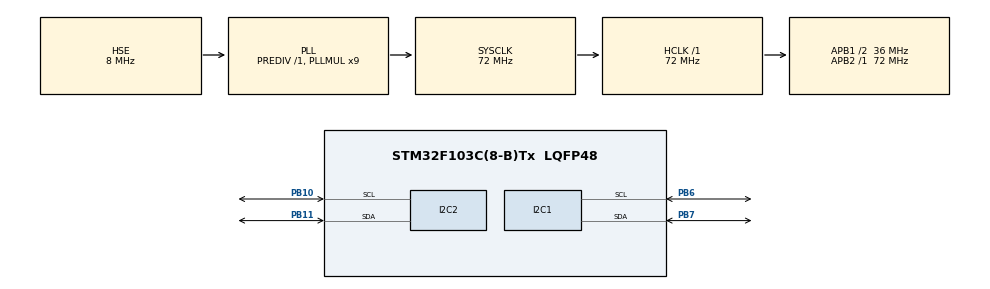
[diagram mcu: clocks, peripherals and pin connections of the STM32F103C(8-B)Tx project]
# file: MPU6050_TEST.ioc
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Mcu.Family=STM32F1
Mcu.Name=STM32F103C(8-B)Tx
Mcu.Package=LQFP48
NVIC.PriorityGroup=NVIC_PRIORITYGROUP_4
PA13.Mode=Serial_Wire
PA13.Signal=SYS_JTMS-SWDIO
PA14.Mode=Serial_Wire
PA14.Signal=SYS_JTCK-SWCLK
PB10.Mode=I2C
PB10.Signal=I2C2_SCL
PB11.Mode=I2C
PB11.Signal=I2C2_SDA
PB6.Mode=I2C
PB6.Signal=I2C1_SCL
PB7.Mode=I2C
PB7.Signal=I2C1_SDA
PC14-OSC32_IN.Mode=LSE-External-Oscillator
PC14-OSC32_IN.Signal=RCC_OSC32_IN
PC15-OSC32_OUT.Mode=LSE-External-Oscillator
PC15-OSC32_OUT.Signal=RCC_OSC32_OUT
PD0-OSC_IN.Mode=HSE-External-Oscillator
PD0-OSC_IN.Signal=RCC_OSC_IN
PD1-OSC_OUT.Mode=HSE-External-Oscillator
PD1-OSC_OUT.Signal=RCC_OSC_OUT
ProjectManager.HeapSize=0x200
ProjectManager.StackSize=0x400
ProjectManager.TargetToolchain=MDK-ARM V5.32
RCC.AHBFreq_Value=72000000
RCC.APB1CLKDivider=RCC_HCLK_DIV2
RCC.APB1Freq_Value=36000000
RCC.APB1TimFreq_Value=72000000
RCC.APB2Freq_Value=72000000
RCC.APB2TimFreq_Value=72000000
RCC.HCLKFreq_Value=72000000
RCC.PLLMUL=RCC_PLL_MUL9
RCC.PLLSourceVirtual=RCC_PLLSOURCE_HSE
RCC.SYSCLKFreq_VALUE=72000000
RCC.SYSCLKSource=RCC_SYSCLKSOURCE_PLLCLK
RCC.USBFreq_Value=72000000
board=custom

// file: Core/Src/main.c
/* USER CODE BEGIN Header */
/**
  ******************************************************************************
  * @file           : main.c
  * @brief          : Main program body
  ******************************************************************************
  * @attention
  *
  * Copyright (c) 2024 STMicroelectronics.
  * All rights reserved.
  *
  * This software is licensed under terms that can be found in the LICENSE file
  * in the root directory of this software component.
  * If no LICENSE file comes with this software, it is provided AS-IS.
  *
  ******************************************************************************
  */
/* USER CODE END Header */
#include "main.h"
#include "i2c.h"
#include "gpio.h"
#include "oled.h"
#include "mpu6050.h"
#include "stdio.h"

uint8_t ID;
uint8_t AX,AY,AZ,GX,GY,GZ,YM;

void SystemClock_Config(void);

int main(void)
{

  /* MCU Configuration--------------------------------------------------------*/

  /* Reset of all peripherals, Initializes the Flash interface and the Systick. */
  HAL_Init();

  /* Configure the system clock */
  SystemClock_Config();

  /* Initialize all configured peripherals */
  MX_GPIO_Init();
  MX_I2C1_Init();
  MX_I2C2_Init();
  /* USER CODE BEGIN 2 */
  HAL_Delay(20);
  OLED_Init();
  MPU6050_Init();

  char message_gx[10];
	char message_gy[10];
	char message_gz[10];
	char message_Ax[10];
	char message_Ay[10];
	char message_Az[10];
  /* USER CODE END 2 */

  /* Infinite loop */
  while (1)
  {
    MPU6050_Read_Accel();
	  MPU6050_Read_Gyro ();
	  sprintf(message_gx,"Gx:%2f",Gx);
		sprintf(message_gy,"Gy:%2f",Gy);
		sprintf(message_gz,"Gz:%2f",Gz);
		sprintf(message_Ax,"Ax:%2f",Ax);
		sprintf(message_Ay,"Ay:%2f",Ay);
		sprintf(message_Az,"Az:%2f",Az);
		OLED_NewFrame();
		OLED_ShowString6X8(0,0,message_gx);
		OLED_ShowString6X8(0,1,message_gy);
		OLED_ShowString6X8(0,2,message_gz);
		OLED_ShowString6X8(0,3,message_Ax);
		OLED_ShowString6X8(0,4,message_Ay);
		OLED_ShowString6X8(0,5,message_Az);
		OLED_ShowFrame();
		HAL_Delay(500);
  }
}

void SystemClock_Config(void)
{
  RCC_OscInitTypeDef RCC_OscInitStruct = {0};
  RCC_ClkInitTypeDef RCC_ClkInitStruct = {0};

  /** Initializes the RCC Oscillators according to the specified parameters
  * in the RCC_OscInitTypeDef structure.
  */
  RCC_OscInitStruct.OscillatorType = RCC_OSCILLATORTYPE_HSE;
  RCC_OscInitStruct.HSEState = RCC_HSE_ON;
  RCC_OscInitStruct.HSEPredivValue = RCC_HSE_PREDIV_DIV1;
  RCC_OscInitStruct.HSIState = RCC_HSI_ON;
  RCC_OscInitStruct.PLL.PLLState = RCC_PLL_ON;
  RCC_OscInitStruct.PLL.PLLSource = RCC_PLLSOURCE_HSE;
  RCC_OscInitStruct.PLL.PLLMUL = RCC_PLL_MUL9;
  if (HAL_RCC_OscConfig(&RCC_OscInitStruct) != HAL_OK)
  {
    Error_Handler();
  }

  /** Initializes the CPU, AHB and APB buses clocks
  */
  RCC_ClkInitStruct.ClockType = RCC_CLOCKTYPE_HCLK|RCC_CLOCKTYPE_SYSCLK
                              |RCC_CLOCKTYPE_PCLK1|RCC_CLOCKTYPE_PCLK2;
  RCC_ClkInitStruct.SYSCLKSource = RCC_SYSCLKSOURCE_PLLCLK;
  RCC_ClkInitStruct.AHBCLKDivider = RCC_SYSCLK_DIV1;
  RCC_ClkInitStruct.APB1CLKDivider = RCC_HCLK_DIV2;
  RCC_ClkInitStruct.APB2CLKDivider = RCC_HCLK_DIV1;

  if (HAL_RCC_ClockConfig(&RCC_ClkInitStruct, FLASH_LATENCY_2) != HAL_OK)
  {
    Error_Handler();
  }
}

void Error_Handler(void)
{
  __disable_irq();
  while (1)
  {
  }
}
